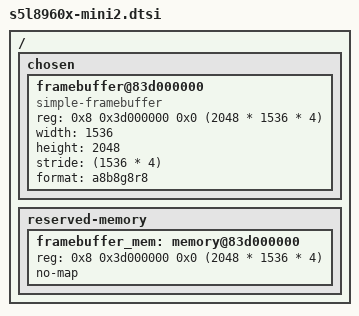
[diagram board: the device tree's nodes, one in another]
// SPDX-License-Identifier: GPL-2.0+ OR MIT
/*
 * Apple iPad Mini 2 common device tree
 * Based on A7 (APL0698), up to 1.3GHz
 *
 * Copyright (c) 2022, Konrad Dybcio <konrad.dybcio@somainline.org>
 */

#include "s5l8960x.dtsi"

/ {
	chosen {
		framebuffer@83d000000 {
			compatible = "simple-framebuffer";
			reg = <0x8 0x3d000000 0x0 (2048 * 1536 * 4)>;
			width = <1536>;
			height = <2048>;
			stride = <(1536 * 4)>;
			format = "a8b8g8r8";
		};
	};

	reserved-memory {
		framebuffer_mem: memory@83d000000 {
			reg = <0x8 0x3d000000 0x0 (2048 * 1536 * 4)>;
			no-map;
		};
	};
};
